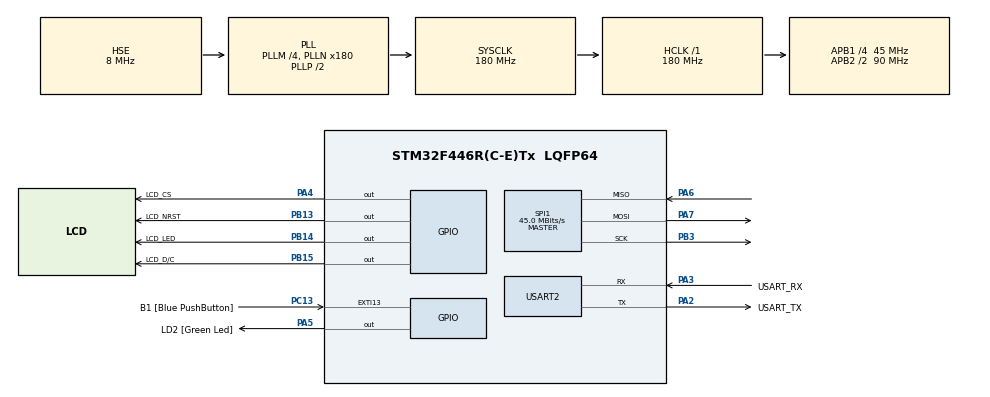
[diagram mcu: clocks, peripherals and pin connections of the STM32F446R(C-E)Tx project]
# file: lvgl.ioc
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Mcu.Family=STM32F4
Mcu.Name=STM32F446R(C-E)Tx
Mcu.Package=LQFP64
NVIC.PriorityGroup=NVIC_PRIORITYGROUP_4
PA13.GPIO_Label=TMS
PA13.Mode=Serial_Wire
PA13.Signal=SYS_JTMS-SWDIO
PA14.GPIO_Label=TCK
PA14.Mode=Serial_Wire
PA14.Signal=SYS_JTCK-SWCLK
PA2.GPIO_Label=USART_TX
PA2.Mode=Asynchronous
PA2.Signal=USART2_TX
PA3.GPIO_Label=USART_RX
PA3.Mode=Asynchronous
PA3.Signal=USART2_RX
PA4.GPIO_Label=LCD_CS
PA4.Signal=GPIO_Output
PA5.GPIO_Label=LD2 [Green Led]
PA5.Signal=GPIO_Output
PA6.Mode=Full_Duplex_Master
PA6.Signal=SPI1_MISO
PA7.Mode=Full_Duplex_Master
PA7.Signal=SPI1_MOSI
PB13.GPIO_Label=LCD_NRST
PB13.Signal=GPIO_Output
PB14.GPIO_Label=LCD_LED
PB14.Signal=GPIO_Output
PB15.GPIO_Label=LCD_D/C
PB15.Signal=GPIO_Output
PB3.Mode=Full_Duplex_Master
PB3.Signal=SPI1_SCK
PC13.GPIO_Label=B1 [Blue PushButton]
PC13.GPIO_ModeDefaultEXTI=GPIO_MODE_IT_FALLING
PC13.Signal=GPXTI13
PH0-OSC_IN.Mode=HSE-External-Oscillator
PH0-OSC_IN.Signal=RCC_OSC_IN
PH1-OSC_OUT.Mode=HSE-External-Oscillator
PH1-OSC_OUT.Signal=RCC_OSC_OUT
ProjectManager.HeapSize=0x2000
ProjectManager.StackSize=0x2000
ProjectManager.TargetToolchain=MDK-ARM V5.32
RCC.48MHZClocksFreq_Value=84000000
RCC.AHBFreq_Value=180000000
RCC.APB1CLKDivider=RCC_HCLK_DIV4
RCC.APB1Freq_Value=45000000
RCC.APB1TimFreq_Value=90000000
RCC.APB2CLKDivider=RCC_HCLK_DIV2
RCC.APB2Freq_Value=90000000
RCC.APB2TimFreq_Value=180000000
RCC.CortexFreq_Value=180000000
RCC.FLatency-AdvancedSettings=FLASH_LATENCY_5
RCC.HCLKFreq_Value=180000000
RCC.HSE_VALUE=8000000
RCC.HSI_VALUE=16000000
RCC.PLLM=4
RCC.PLLN=180
RCC.PLLSourceVirtual=RCC_PLLSOURCE_HSE
RCC.SYSCLKFreq_VALUE=180000000
RCC.SYSCLKSource=RCC_SYSCLKSOURCE_PLLCLK
RCC.USBFreq_Value=180000000
RCC.VCOOutputFreq_Value=360000000
SPI1.BaudRatePrescaler=SPI_BAUDRATEPRESCALER_2
SPI1.CLKPhase=SPI_PHASE_1EDGE
SPI1.CLKPolarity=SPI_POLARITY_LOW
SPI1.CRCCalculation=SPI_CRCCALCULATION_DISABLE
SPI1.CalculateBaudRate=45.0 MBits/s
SPI1.Direction=SPI_DIRECTION_2LINES
SPI1.Mode=SPI_MODE_MASTER
SPI1.VirtualType=VM_MASTER
USART2.VirtualMode=VM_ASYNC
board=NUCLEO-F446RE

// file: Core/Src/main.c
/* USER CODE BEGIN Header */
/**
  ******************************************************************************
  * @file           : main.c
  * @brief          : Main program body
  ******************************************************************************
  * @attention
  *
  * Copyright (c) 2023 STMicroelectronics.
  * All rights reserved.
  *
  * This software is licensed under terms that can be found in the LICENSE file
  * in the root directory of this software component.
  * If no LICENSE file comes with this software, it is provided AS-IS.
  *
  ******************************************************************************
  */
/* USER CODE END Header */
#include "main.h"
#include "spi.h"
#include "usart.h"
#include "gpio.h"

/* USER CODE BEGIN Includes */
#include "st7735s.h"
#include "lv_port_disp_template.h"
#include "lv_demo_benchmark.h"
#include <lvgl.h>
/* USER CODE END Includes */

void SystemClock_Config(void);

int main(void)
{

  /* MCU Configuration--------------------------------------------------------*/

  /* Reset of all peripherals, Initializes the Flash interface and the Systick. */
  HAL_Init();

  /* Configure the system clock */
  SystemClock_Config();

  /* Initialize all configured peripherals */
  MX_GPIO_Init();
  MX_USART2_UART_Init();
  MX_SPI1_Init();
  /* USER CODE BEGIN 2 */
	lv_init();
	lv_port_disp_init();
	lv_demo_benchmark(LV_DEMO_BENCHMARK_MODE_RENDER_AND_DRIVER);

  /* USER CODE END 2 */

  /* Infinite loop */
  /* USER CODE BEGIN WHILE */
  while (1)
  {
		lv_task_handler();
		HAL_Delay(5);
//		HAL_GPIO_TogglePin(LD2_GPIO_Port, LD2_Pin);
//		HAL_Delay(300);
    /* USER CODE END WHILE */

  }
}

void SystemClock_Config(void)
{
  RCC_OscInitTypeDef RCC_OscInitStruct = {0};
  RCC_ClkInitTypeDef RCC_ClkInitStruct = {0};

  /** Configure the main internal regulator output voltage
  */
  __HAL_RCC_PWR_CLK_ENABLE();
  __HAL_PWR_VOLTAGESCALING_CONFIG(PWR_REGULATOR_VOLTAGE_SCALE1);

  /** Initializes the RCC Oscillators according to the specified parameters
  * in the RCC_OscInitTypeDef structure.
  */
  RCC_OscInitStruct.OscillatorType = RCC_OSCILLATORTYPE_HSE;
  RCC_OscInitStruct.HSEState = RCC_HSE_ON;
  RCC_OscInitStruct.PLL.PLLState = RCC_PLL_ON;
  RCC_OscInitStruct.PLL.PLLSource = RCC_PLLSOURCE_HSE;
  RCC_OscInitStruct.PLL.PLLM = 4;
  RCC_OscInitStruct.PLL.PLLN = 180;
  RCC_OscInitStruct.PLL.PLLP = RCC_PLLP_DIV2;
  RCC_OscInitStruct.PLL.PLLQ = 2;
  RCC_OscInitStruct.PLL.PLLR = 2;
  if (HAL_RCC_OscConfig(&RCC_OscInitStruct) != HAL_OK)
  {
    Error_Handler();
  }

  /** Activate the Over-Drive mode
  */
  if (HAL_PWREx_EnableOverDrive() != HAL_OK)
  {
    Error_Handler();
  }

  /** Initializes the CPU, AHB and APB buses clocks
  */
  RCC_ClkInitStruct.ClockType = RCC_CLOCKTYPE_HCLK|RCC_CLOCKTYPE_SYSCLK
                              |RCC_CLOCKTYPE_PCLK1|RCC_CLOCKTYPE_PCLK2;
  RCC_ClkInitStruct.SYSCLKSource = RCC_SYSCLKSOURCE_PLLCLK;
  RCC_ClkInitStruct.AHBCLKDivider = RCC_SYSCLK_DIV1;
  RCC_ClkInitStruct.APB1CLKDivider = RCC_HCLK_DIV4;
  RCC_ClkInitStruct.APB2CLKDivider = RCC_HCLK_DIV2;

  if (HAL_RCC_ClockConfig(&RCC_ClkInitStruct, FLASH_LATENCY_5) != HAL_OK)
  {
    Error_Handler();
  }
}

void Error_Handler(void)
{
  __disable_irq();
  while (1)
  {
  }
}
